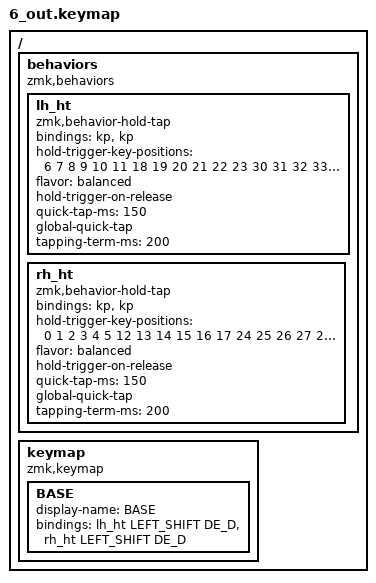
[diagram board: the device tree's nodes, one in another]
/ {
    behaviors {
        compatible = "zmk,behaviors";

        // BEGIN behaviors
        lh_ht: lh_ht {
            compatible = "zmk,behavior-hold-tap";
            #binding-cells = <2>;
            bindings = <&kp>, <&kp>;
            hold-trigger-key-positions = <6 7 8 9 10 11 18 19 20 21 22 23 30 31 32 33 34 35>;
            flavor = "balanced";
            hold-trigger-on-release;
            quick-tap-ms = <150>;
            global-quick-tap;
            tapping-term-ms = <200>;
        };

        rh_ht: rh_ht {
            compatible = "zmk,behavior-hold-tap";
            #binding-cells = <2>;
            bindings = <&kp>, <&kp>;
            hold-trigger-key-positions = <0 1 2 3 4 5 12 13 14 15 16 17 24 25 26 27 28 29>;
            flavor = "balanced";
            hold-trigger-on-release;
            quick-tap-ms = <150>;
            global-quick-tap;
            tapping-term-ms = <200>;
        };
        // END behaviors
    };

    keymap {
        compatible = "zmk,keymap";

        // BEGIN keymap
        BASE {
            display-name = "BASE";
            bindings = <
&lh_ht LEFT_SHIFT DE_D
&rh_ht LEFT_SHIFT DE_D
            >;
        };
        // END keymap
    };
};

